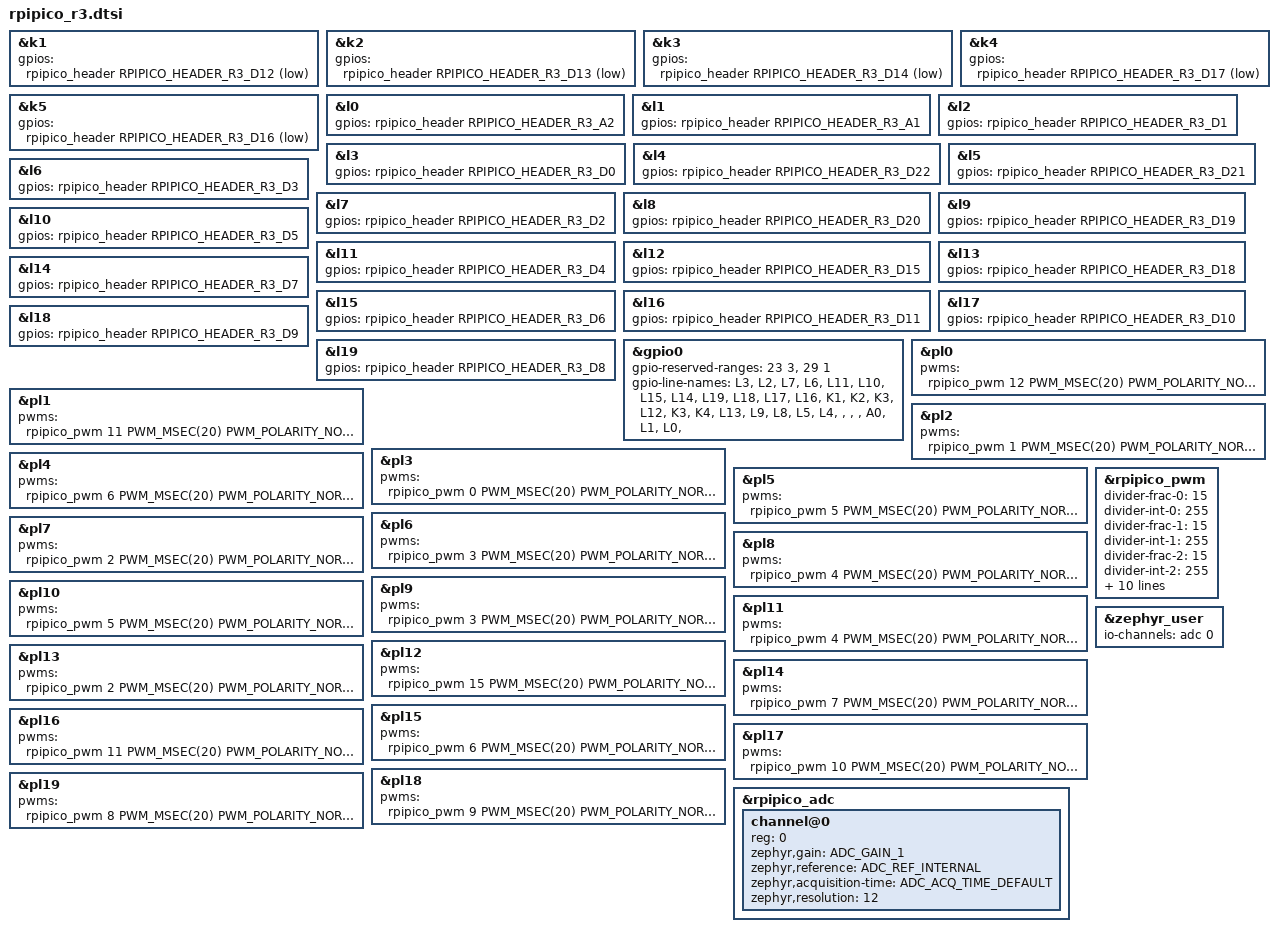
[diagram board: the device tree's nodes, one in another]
/*
 * SPDX-FileCopyrightText: Copyright (c) 2023-2026 TiaC Systems
 * SPDX-License-Identifier: Apache-2.0
 */

#include "rpipico_r3-connect.dtsi"

#include <zephyr/dt-bindings/gpio/gpio.h>
#include <zephyr/dt-bindings/pwm/pwm.h>

#include <zephyr/dt-bindings/gpio/raspberrypi-pico-header-r3.h>

&k1 {	/* GP12:GPIO */
	gpios = <&rpipico_header RPIPICO_HEADER_R3_D12 (GPIO_PULL_UP | GPIO_ACTIVE_LOW)>;
};

&k2 {	/* GP13:GPIO */
	gpios = <&rpipico_header RPIPICO_HEADER_R3_D13 (GPIO_PULL_UP | GPIO_ACTIVE_LOW)>;
};

&k3 {	/* GP14:GPIO */
	gpios = <&rpipico_header RPIPICO_HEADER_R3_D14 (GPIO_PULL_UP | GPIO_ACTIVE_LOW)>;
};

&k4 {	/* GP17:GPIO */
	gpios = <&rpipico_header RPIPICO_HEADER_R3_D17 (GPIO_PULL_UP | GPIO_ACTIVE_LOW)>;
};

&k5 {	/* GP16:GPIO */
	gpios = <&rpipico_header RPIPICO_HEADER_R3_D16 (GPIO_PULL_UP | GPIO_ACTIVE_LOW)>;
};

&l0 {	/* GP28:GPIO */
	gpios = <&rpipico_header RPIPICO_HEADER_R3_A2 GPIO_ACTIVE_HIGH>;
};

&l1 {	/* GP27:GPIO */
	gpios = <&rpipico_header RPIPICO_HEADER_R3_A1 GPIO_ACTIVE_HIGH>;
};

&l2 {	/* GP1:GPIO */
	gpios = <&rpipico_header RPIPICO_HEADER_R3_D1 GPIO_ACTIVE_HIGH>;
};

&l3 {	/* GP0:GPIO */
	gpios = <&rpipico_header RPIPICO_HEADER_R3_D0 GPIO_ACTIVE_HIGH>;
};

&l4 {	/* GP22:GPIO */
	gpios = <&rpipico_header RPIPICO_HEADER_R3_D22 GPIO_ACTIVE_HIGH>;
};

&l5 {	/* GP21:GPIO */
	gpios = <&rpipico_header RPIPICO_HEADER_R3_D21 GPIO_ACTIVE_HIGH>;
};

&l6 {	/* GP3:GPIO */
	gpios = <&rpipico_header RPIPICO_HEADER_R3_D3 GPIO_ACTIVE_HIGH>;
};

&l7 {	/* GP2:GPIO */
	gpios = <&rpipico_header RPIPICO_HEADER_R3_D2 GPIO_ACTIVE_HIGH>;
};

&l8 {	/* GP20:GPIO */
	gpios = <&rpipico_header RPIPICO_HEADER_R3_D20 GPIO_ACTIVE_HIGH>;
};

&l9 {	/* GP19:GPIO */
	gpios = <&rpipico_header RPIPICO_HEADER_R3_D19 GPIO_ACTIVE_HIGH>;
};

&l10 {	/* GP5:GPIO */
	gpios = <&rpipico_header RPIPICO_HEADER_R3_D5 GPIO_ACTIVE_HIGH>;
};

&l11 {	/* GP4:GPIO */
	gpios = <&rpipico_header RPIPICO_HEADER_R3_D4 GPIO_ACTIVE_HIGH>;
};

&l12 {	/* GP15:GPIO */
	gpios = <&rpipico_header RPIPICO_HEADER_R3_D15 GPIO_ACTIVE_HIGH>;
};

&l13 {	/* GP18:GPIO */
	gpios = <&rpipico_header RPIPICO_HEADER_R3_D18 GPIO_ACTIVE_HIGH>;
};

&l14 {	/* GP7:GPIO */
	gpios = <&rpipico_header RPIPICO_HEADER_R3_D7 GPIO_ACTIVE_HIGH>;
};

&l15 {	/* GP6:GPIO */
	gpios = <&rpipico_header RPIPICO_HEADER_R3_D6 GPIO_ACTIVE_HIGH>;
};

&l16 {	/* GP11:GPIO */
	gpios = <&rpipico_header RPIPICO_HEADER_R3_D11 GPIO_ACTIVE_HIGH>;
};

&l17 {	/* GP10:GPIO */
	gpios = <&rpipico_header RPIPICO_HEADER_R3_D10 GPIO_ACTIVE_HIGH>;
};

&l18 {	/* GP9:GPIO */
	gpios = <&rpipico_header RPIPICO_HEADER_R3_D9 GPIO_ACTIVE_HIGH>;
};

&l19 {	/* GP8:GPIO */
	gpios = <&rpipico_header RPIPICO_HEADER_R3_D8 GPIO_ACTIVE_HIGH>;
};

&gpio0 {
	status = "okay";
	/* namespace and positions without wired bits */
	gpio-reserved-ranges = <23 3>, <29 1>;
	gpio-line-names =
		"L3",		/* GP0 */
		"L2",		/* GP1 */
		"L7",		/* GP2 */
		"L6",		/* GP3 */
		"L11",		/* GP4 */
		"L10",		/* GP5 */
		"L15",		/* GP6 */
		"L14",		/* GP7 */
		"L19",		/* GP8 */
		"L18",		/* GP9 */
		"L17",		/* GP10 */
		"L16",		/* GP11 */
		"K1",		/* GP12 */
		"K2",		/* GP13 */
		"K3",		/* GP14 */
		"L12",		/* GP15 */
		"K3",		/* GP16 */
		"K4",		/* GP17 */
		"L13",		/* GP18 */
		"L9",		/* GP19 */
		"L8",		/* GP20 */
		"L5",		/* GP21 */
		"L4",		/* GP22 */
		"",  /* not wired, GP23 */
		"",  /* not wired, GP24 */
		"",  /* not wired, GP25 */
		"A0",		/* GP26 */
		"L1",		/* GP27 */
		"L0",		/* GP28 */
		"";  /* not wired, GP29 */
};

&pl0 {	/* GP28:PWM6A */
	pwms = <&rpipico_pwm 12 PWM_MSEC(20) PWM_POLARITY_NORMAL>;
};

&pl1 {	/* GP27:PWM5B */
	pwms = <&rpipico_pwm 11 PWM_MSEC(20) PWM_POLARITY_NORMAL>;
};

&pl2 {	/* GP1:PWM0B */
	pwms = <&rpipico_pwm 1 PWM_MSEC(20) PWM_POLARITY_NORMAL>;
};

&pl3 {	/* GP0:PWM0A */
	pwms = <&rpipico_pwm 0 PWM_MSEC(20) PWM_POLARITY_NORMAL>;
};

&pl4 {	/* GP22:PWM3A */
	pwms = <&rpipico_pwm 6 PWM_MSEC(20) PWM_POLARITY_NORMAL>;
};

&pl5 {	/* GP21:PWM2B */
	pwms = <&rpipico_pwm 5 PWM_MSEC(20) PWM_POLARITY_NORMAL>;
};

&pl6 {	/* GP3:PWM1B */
	pwms = <&rpipico_pwm 3 PWM_MSEC(20) PWM_POLARITY_NORMAL>;
};

&pl7 {	/* GP2:PWM1A */
	pwms = <&rpipico_pwm 2 PWM_MSEC(20) PWM_POLARITY_NORMAL>;
};

&pl8 {	/* GP20:PWM2A */
	pwms = <&rpipico_pwm 4 PWM_MSEC(20) PWM_POLARITY_NORMAL>;
};

&pl9 {	/* GP19:PWM1B */
	pwms = <&rpipico_pwm 3 PWM_MSEC(20) PWM_POLARITY_NORMAL>;
};

&pl10 {	/* GP5:PWM2B */
	pwms = <&rpipico_pwm 5 PWM_MSEC(20) PWM_POLARITY_NORMAL>;
};

&pl11 {	/* GP4:PWM2A */
	pwms = <&rpipico_pwm 4 PWM_MSEC(20) PWM_POLARITY_NORMAL>;
};

&pl12 {	/* GP15:PWM7B */
	pwms = <&rpipico_pwm 15 PWM_MSEC(20) PWM_POLARITY_NORMAL>;
};

&pl13 {	/* GP18:PWM1A */
	pwms = <&rpipico_pwm 2 PWM_MSEC(20) PWM_POLARITY_NORMAL>;
};

&pl14 {	/* GP7:PWM3B */
	pwms = <&rpipico_pwm 7 PWM_MSEC(20) PWM_POLARITY_NORMAL>;
};

&pl15 {	/* GP6:PWM3A */
	pwms = <&rpipico_pwm 6 PWM_MSEC(20) PWM_POLARITY_NORMAL>;
};

&pl16 {	/* GP11:PWM5B */
	pwms = <&rpipico_pwm 11 PWM_MSEC(20) PWM_POLARITY_NORMAL>;
};

&pl17 {	/* GP10:PWM5A */
	pwms = <&rpipico_pwm 10 PWM_MSEC(20) PWM_POLARITY_NORMAL>;
};

&pl18 {	/* GP9:PWM4B */
	pwms = <&rpipico_pwm 9 PWM_MSEC(20) PWM_POLARITY_NORMAL>;
};

&pl19 {	/* GP8:PWM4A */
	pwms = <&rpipico_pwm 8 PWM_MSEC(20) PWM_POLARITY_NORMAL>;
};

&rpipico_pwm {
	status = "okay";
	divider-frac-0 = <15>;
	divider-int-0 = <255>;
	divider-frac-1 = <15>;
	divider-int-1 = <255>;
	divider-frac-2 = <15>;
	divider-int-2 = <255>;
	divider-frac-3 = <15>;
	divider-int-3 = <255>;
	divider-frac-4 = <15>;
	divider-int-4 = <255>;
	divider-frac-5 = <15>;
	divider-int-5 = <255>;
	divider-frac-6 = <15>;
	divider-int-6 = <255>;
	divider-frac-7 = <15>;
	divider-int-7 = <255>;
};

&zephyr_user {	/* GP26:ADC0 */
	io-channels = <&adc 0>;
};

&rpipico_adc {
	status = "okay";

	#address-cells = <1>;
	#size-cells = <0>;

	/delete-node/ channel@0;
	channel@0 {
		reg = <0>;
		zephyr,gain = "ADC_GAIN_1";
		zephyr,reference = "ADC_REF_INTERNAL";
		zephyr,acquisition-time = <ADC_ACQ_TIME_DEFAULT>;
		zephyr,resolution = <12>;
	};

	/delete-node/ channel@1;
	/delete-node/ channel@2;
	/delete-node/ channel@3;
};
